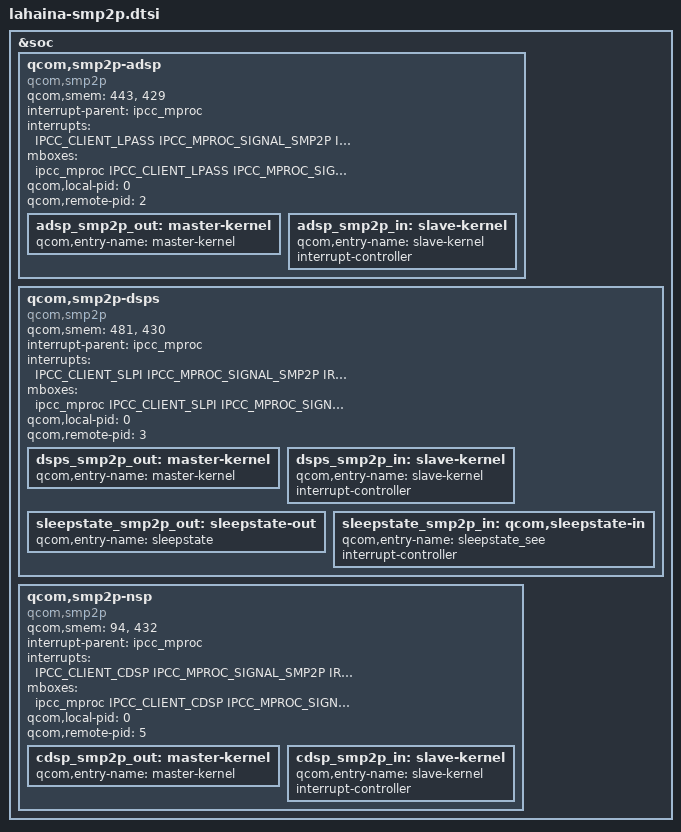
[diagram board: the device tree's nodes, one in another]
#include <dt-bindings/interrupt-controller/arm-gic.h>
#include <dt-bindings/soc/qcom,ipcc.h>

&soc {
	qcom,smp2p-adsp {
		compatible = "qcom,smp2p";
		qcom,smem = <443>, <429>;
		interrupt-parent = <&ipcc_mproc>;
		interrupts = <IPCC_CLIENT_LPASS IPCC_MPROC_SIGNAL_SMP2P
			      IRQ_TYPE_EDGE_RISING>;
		mboxes = <&ipcc_mproc IPCC_CLIENT_LPASS
			  IPCC_MPROC_SIGNAL_SMP2P>;
		qcom,local-pid = <0>;
		qcom,remote-pid = <2>;

		adsp_smp2p_out: master-kernel {
			qcom,entry-name = "master-kernel";
			#qcom,smem-state-cells = <1>;
		};

		adsp_smp2p_in: slave-kernel {
			qcom,entry-name = "slave-kernel";
			interrupt-controller;
			#interrupt-cells = <2>;
		};
	};

	qcom,smp2p-dsps {
		compatible = "qcom,smp2p";
		qcom,smem = <481>, <430>;
		interrupt-parent = <&ipcc_mproc>;
		interrupts = <IPCC_CLIENT_SLPI IPCC_MPROC_SIGNAL_SMP2P
			      IRQ_TYPE_EDGE_RISING>;
		mboxes = <&ipcc_mproc IPCC_CLIENT_SLPI IPCC_MPROC_SIGNAL_SMP2P>;
		qcom,local-pid = <0>;
		qcom,remote-pid = <3>;

		dsps_smp2p_out: master-kernel {
			qcom,entry-name = "master-kernel";
			#qcom,smem-state-cells = <1>;
		};

		dsps_smp2p_in: slave-kernel {
			qcom,entry-name = "slave-kernel";
			interrupt-controller;
			#interrupt-cells = <2>;
		};

		sleepstate_smp2p_out: sleepstate-out {
			qcom,entry-name = "sleepstate";
			#qcom,smem-state-cells = <1>;
		};

		sleepstate_smp2p_in: qcom,sleepstate-in {
			qcom,entry-name = "sleepstate_see";
			interrupt-controller;
			#interrupt-cells = <2>;
		};
	};

	qcom,smp2p-nsp {
		compatible = "qcom,smp2p";
		qcom,smem = <94>, <432>;
		interrupt-parent = <&ipcc_mproc>;
		interrupts = <IPCC_CLIENT_CDSP IPCC_MPROC_SIGNAL_SMP2P
			      IRQ_TYPE_EDGE_RISING>;
		mboxes = <&ipcc_mproc IPCC_CLIENT_CDSP IPCC_MPROC_SIGNAL_SMP2P>;
		qcom,local-pid = <0>;
		qcom,remote-pid = <5>;

		cdsp_smp2p_out: master-kernel {
			qcom,entry-name = "master-kernel";
			#qcom,smem-state-cells = <1>;
		};

		cdsp_smp2p_in: slave-kernel {
			qcom,entry-name = "slave-kernel";
			interrupt-controller;
			#interrupt-cells = <2>;
		};
	};
};
